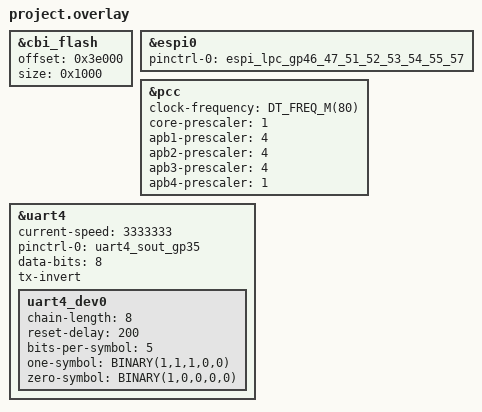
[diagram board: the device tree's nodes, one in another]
/* Copyright 2025 The ChromiumOS Authors
 * Use of this source code is governed by a BSD-style license that can be
 * found in the LICENSE file.
 */

/* Include the standard and OEM schema templates */
#include <cros/cbi_ufsc_std_schema.dtsi>
#include <cros/cbi_ufsc_oem_schema.dtsi>

/* ruby program common DTS includes */

#include <cros/cbi_flash.dtsi>

#include <cros/integrated_fwid.dtsi>
#include <dt-bindings/macros.h>
#include <zephyr/dt-bindings/led/led.h>

#include "adc.dtsi"
#include "battery.dtsi"
#include "cbi.dtsi"
#include "gpios.dtsi"
#include "i2c.dtsi"
#include "keyboard.dtsi"
#include "led_pins.dtsi"
#include "led_policy.dtsi"
#include "overlay.dtsi"
#include "power_signals.dtsi"
#include "ruby_ec_ufsc.dtsi"
#include "thermal.dtsi"
#include "usba.dtsi"
#include "usbc.dtsi"
#include <ruby/overlay.dtsi>

/* ruby overrides follow... */

&cbi_flash {
	/*
	 * CBI section size is 0x1000 bytes, the CBI portion lies at the end of
	 * EC_RO section. EC_RO section ends at 0x40000 byte which is the offset
	 */
	offset = <0x3e000>;
	size = <0x1000>;
};


/* AP interface */
&espi0 {
	status = "okay";
	pinctrl-0 = <&espi_lpc_gp46_47_51_52_53_54_55_57>;
	pinctrl-names = "default";
};

/* DT Overlay (e.g. project.overlay) for current-speed = <3333333> */
&pcc {
	clock-frequency = <DT_FREQ_M(80)>; /* OFMCLK runs at 80 MHz */
	core-prescaler = <1>; /* CORE_CLK runs at 80 MHz */
	apb1-prescaler = <4>; /* APB1_CLK runs at 20 MHz */
	apb2-prescaler = <4>; /* APB2_CLK runs at 20 MHz */
	apb3-prescaler = <4>; /* APB3_CLK runs at 20 MHz */
	/*
	 * APB4_CLK runs at 80 MHz, required to support
	 * UART4 Baudrate=3.333333 MHz
	 */
	apb4-prescaler = <1>;
};

&uart4 {
    status = "okay";
    current-speed = <3333333>;      // 3.333333 MHz baud rate
    pinctrl-0 = <&uart4_sout_gp35>; // Configure the specific TX pin
    pinctrl-names = "default";
    data-bits = <8>;                // (2+8=10, a multiple of 5)
    tx-invert;                      // Mandatory for idle-low signal

    uart4_dev0: uart4_dev0 {
        status = "okay";
        chain-length = <8>;
        reset-delay = <200>;
        bits-per-symbol = <5>;
        one-symbol = <BINARY(1,1,1,0,0)>;
        zero-symbol = <BINARY(1,0,0,0,0)>;
    };
};
